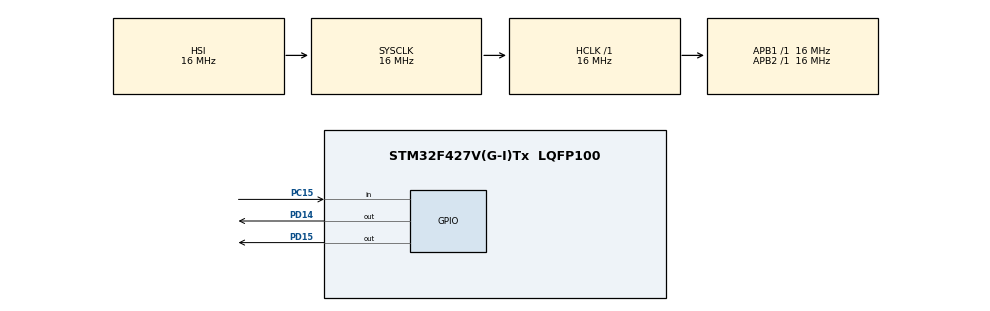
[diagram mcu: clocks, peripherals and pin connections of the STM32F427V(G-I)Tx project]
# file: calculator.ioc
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Mcu.Family=STM32F4
Mcu.Name=STM32F427V(G-I)Tx
Mcu.Package=LQFP100
NVIC.PriorityGroup=NVIC_PRIORITYGROUP_4
PA13.Mode=JTAG_5_pins
PA13.Signal=SYS_JTMS-SWDIO
PA14.Mode=JTAG_5_pins
PA14.Signal=SYS_JTCK-SWCLK
PA15.Mode=JTAG_5_pins
PA15.Signal=SYS_JTDI
PB3.Mode=JTAG_5_pins
PB3.Signal=SYS_JTDO-SWO
PB4.Mode=JTAG_5_pins
PB4.Signal=SYS_JTRST
PC15/OSC32_OUT.GPIO_PuPd=GPIO_PULLUP
PC15/OSC32_OUT.Signal=GPIO_Input
PD14.GPIO_PuPd=GPIO_PULLDOWN
PD14.Signal=GPIO_Output
PD15.GPIO_PuPd=GPIO_PULLDOWN
PD15.Signal=GPIO_Output
ProjectManager.HeapSize=0x200
ProjectManager.StackSize=0x400
ProjectManager.TargetToolchain=STM32CubeIDE
RCC.AHBFreq_Value=16000000
RCC.APB1Freq_Value=16000000
RCC.APB2Freq_Value=16000000
RCC.CortexFreq_Value=16000000
RCC.HSE_VALUE=25000000
RCC.HSI_VALUE=16000000
RCC.LSE_VALUE=32768
RCC.SYSCLKFreq_VALUE=16000000
RCC.VCOOutputFreq_Value=192000000
board=custom

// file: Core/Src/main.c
/* USER CODE BEGIN Header */
/**
  ******************************************************************************
  * @file           : main.c
  * @brief          : Lab 2, Part 2 (Custom Register-level UART Driver)
  ******************************************************************************
  */
/* USER CODE END Header */
#include "main.h"
#include "gpio.h"

/* USER CODE BEGIN Includes */
#include "board.h"
#include "custom_uart.h"
#include "calculator.h"
/* USER CODE END Includes */

void SystemClock_Config(void);

/* USER CODE BEGIN 0 */
static void Handle_ModeSwitch(void) {
    if (CustomUart_GetMode() == CUSTOM_UART_MODE_INTERRUPT) {
        CustomUart_SetMode(CUSTOM_UART_MODE_POLLING);
        CustomUart_SendString("\r\n[Custom Driver: POLLING (No Interrupts)]\r\n");
    } else {
        CustomUart_SetMode(CUSTOM_UART_MODE_INTERRUPT);
        CustomUart_SendString("\r\n[Custom Driver: INTERRUPTS]\r\n");
    }

    Calculator_Reset();
    CustomUart_SendString("Enter expression (e.g. 12+34=):\r\n");
}
/* USER CODE END 0 */

int main(void)
{
  HAL_Init();
  SystemClock_Config();

  MX_GPIO_Init();

  /* USER CODE BEGIN 2 */
  Board_Init();

  CustomUart_Init(19200, CUSTOM_UART_MODE_INTERRUPT);
  Calculator_Init();

  CustomUart_SendString("\r\n--- Stand SDK-1.1M Ready (Custom Register UART Driver) ---\r\n");
  CustomUart_SendString("[Custom Driver: INTERRUPTS]\r\n");
  CustomUart_SendString("Enter expression (e.g. 12+34=):\r\n");
  /* USER CODE END 2 */

  /* Infinite loop */
  /* USER CODE BEGIN WHILE */
  while (1)
  {
      if (Board_Button_IsPressed()) {
          Handle_ModeSwitch();
      }

      uint8_t received_char;
      if (CustomUart_ReceiveByte(&received_char)) {
          if (received_char != '\r' && received_char != '\n') {
              Calculator_ProcessChar(received_char);
          }
      }
    /* USER CODE END WHILE */

  }
}

void SystemClock_Config(void)
{
  RCC_OscInitTypeDef RCC_OscInitStruct = {0};
  RCC_ClkInitTypeDef RCC_ClkInitStruct = {0};

  /** Configure the main internal regulator output voltage
  */
  __HAL_RCC_PWR_CLK_ENABLE();
  __HAL_PWR_VOLTAGESCALING_CONFIG(PWR_REGULATOR_VOLTAGE_SCALE3);

  /** Initializes the RCC Oscillators according to the specified parameters
  * in the RCC_OscInitTypeDef structure.
  */
  RCC_OscInitStruct.OscillatorType = RCC_OSCILLATORTYPE_HSI;
  RCC_OscInitStruct.HSIState = RCC_HSI_ON;
  RCC_OscInitStruct.HSICalibrationValue = RCC_HSICALIBRATION_DEFAULT;
  RCC_OscInitStruct.PLL.PLLState = RCC_PLL_NONE;
  if (HAL_RCC_OscConfig(&RCC_OscInitStruct) != HAL_OK)
  {
    Error_Handler();
  }

  /** Initializes the CPU, AHB and APB buses clocks
  */
  RCC_ClkInitStruct.ClockType = RCC_CLOCKTYPE_HCLK|RCC_CLOCKTYPE_SYSCLK
                              |RCC_CLOCKTYPE_PCLK1|RCC_CLOCKTYPE_PCLK2;
  RCC_ClkInitStruct.SYSCLKSource = RCC_SYSCLKSOURCE_HSI;
  RCC_ClkInitStruct.AHBCLKDivider = RCC_SYSCLK_DIV1;
  RCC_ClkInitStruct.APB1CLKDivider = RCC_HCLK_DIV1;
  RCC_ClkInitStruct.APB2CLKDivider = RCC_HCLK_DIV1;

  if (HAL_RCC_ClockConfig(&RCC_ClkInitStruct, FLASH_LATENCY_0) != HAL_OK)
  {
    Error_Handler();
  }
}

void Error_Handler(void)
{
  __disable_irq();
  while (1)
  {
  }
}
